# ESP32-S31 register map
Vendor: ESPRESSIF SYSTEMS (SHANGHAI) CO., LTD.; Series: ESP32 S-Series; File version: 1
CPU: RV32IMAFC r0p0, little endian, no MPU, FPU, 0 interrupt priority bits
Address unit: 32 bits
Registers are 32-bit, read-write, reset 0x0 unless marked. A register's access mark holds for its fields unless they carry their own. Offsets are from the block's base; [hi:lo] are bit positions; {n}, {i} and the like mark numbered series.

## KEYMNG — KEYMNG Peripheral
Base 0x20506000
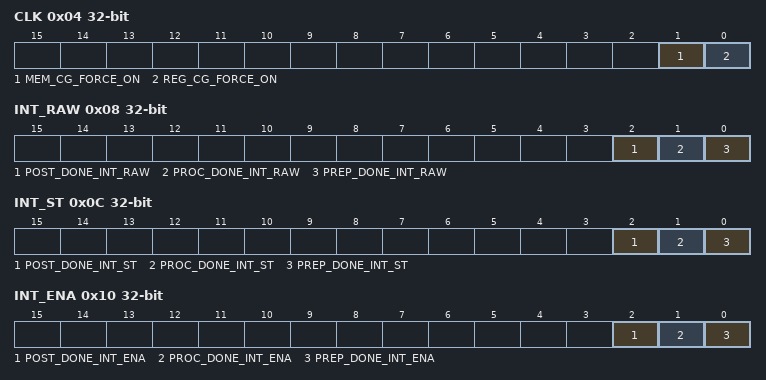
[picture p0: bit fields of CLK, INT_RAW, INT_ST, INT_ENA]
0x04 CLK — Key Manager clock gate control register
  [1] MEM_CG_FORCE_ON — Write 1 to force on memory clock gate.
  [0] REG_CG_FORCE_ON — Write 1 to force on register clock gate.
0x08 INT_RAW ro — Key Manager interrupt raw register, valid in level.
  [2] POST_DONE_INT_RAW — The raw interrupt status bit for the km_post_done_int interrupt
  [1] PROC_DONE_INT_RAW — The raw interrupt status bit for the km_proc_done_int interrupt
  [0] PREP_DONE_INT_RAW — The raw interrupt status bit for the km_prep_done_int interrupt
0x0C INT_ST ro — Key Manager interrupt status register.
  [2] POST_DONE_INT_ST — The masked interrupt status bit for the km_post_done_int interrupt
  [1] PROC_DONE_INT_ST — The masked interrupt status bit for the km_proc_done_int interrupt
  [0] PREP_DONE_INT_ST — The masked interrupt status bit for the km_prep_done_int interrupt
0x10 INT_ENA — Key Manager interrupt enable register.
  [2] POST_DONE_INT_ENA — The interrupt enable bit for the km_post_done_int interrupt
  [1] PROC_DONE_INT_ENA — The interrupt enable bit for the km_proc_done_int interrupt
  [0] PREP_DONE_INT_ENA — The interrupt enable bit for the km_prep_done_int interrupt
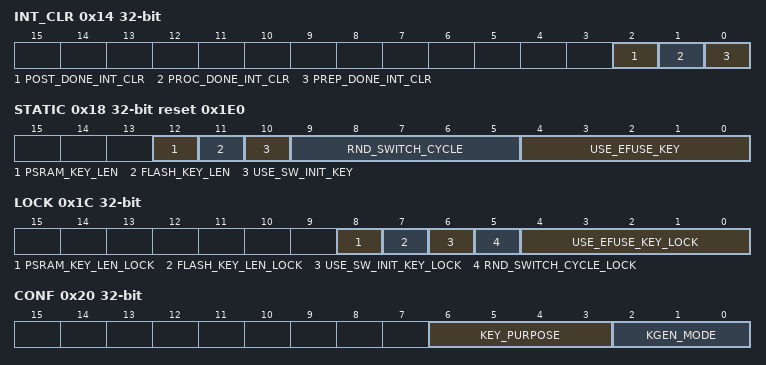
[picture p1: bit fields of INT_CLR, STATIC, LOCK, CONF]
0x14 INT_CLR wo — Key Manager interrupt clear register.
  [2] POST_DONE_INT_CLR — Set this bit to clear the km_post_done_int interrupt
  [1] PROC_DONE_INT_CLR — Set this bit to clear the km_proc_done_int interrupt
  [0] PREP_DONE_INT_CLR — Set this bit to clear the km_prep_done_int interrupt
0x18 STATIC reset 0x1E0 — Key Manager static configuration register
  [12] PSRAM_KEY_LEN — Set this bit to choose psram crypt using xts-aes-256 or xts-aes-128. 1: use xts-aes-256. 0: use xts-aes-128.
  [11] FLASH_KEY_LEN — Set this bit to choose flash crypt using xts-aes-256 or xts-aes-128. 1: use xts-aes-256. 0: use xts-aes-128.
  [10] USE_SW_INIT_KEY — Set this bit to use software written init key instead of efuse_init_key.
  [9:5] RND_SWITCH_CYCLE — The core clock cycle number to sample one rng input data. Please set it bigger than the clock cycle ratio: T_rng/T_km
  [4:0] USE_EFUSE_KEY — Set each bit to choose efuse key instead of key manager deployed key. Each bit stands for a key type:bit 4 for psram_key; bit 3 for ds_key; bit 2 for hmac_key; bit 1 for flash_key; bit 0 for ecdsa_key
0x1C LOCK — Key Manager static configuration locker register
  [8] PSRAM_KEY_LEN_LOCK — Write 1 to lock reg_psram_key_len.
  [7] FLASH_KEY_LEN_LOCK — Write 1 to lock reg_flash_key_len.
  [6] USE_SW_INIT_KEY_LOCK — Write 1 to lock reg_use_sw_init_key.
  [5] RND_SWITCH_CYCLE_LOCK — Write 1 to lock reg_rnd_switch_cycle.
  [4:0] USE_EFUSE_KEY_LOCK — Write 1 to lock reg_use_efuse_key. Each bit locks the corresponding bit of reg_use_efuse_key.
0x20 CONF — Key Manager configuration register
  [6:3] KEY_PURPOSE — Set this field to choose the key purpose. 1: ecdsa_key_192. 2: ecdsa_key_256. 3: flash_256_1_key. 4: flash_256_2_key. 5: flash_128_key. 6: hmac_key. 7: ds_key. 8: psram_256_1_key. 9: psram_256_2_key. 10: psram_128_key. 11: ecdsa_key_384_l. 12: ecdsa_key_384_h. 13: aes 14: mspi_lsfr 15: rma_nonce. Others: reserved.
  [2:0] KGEN_MODE — Set this field to choose the key generator deployment mode. 0: random mode. 1: AES mode. 2: ECDH0 mode. 3: ECDH1 mode. 4: recover mode. 5: export mode. 6-7: reserved.
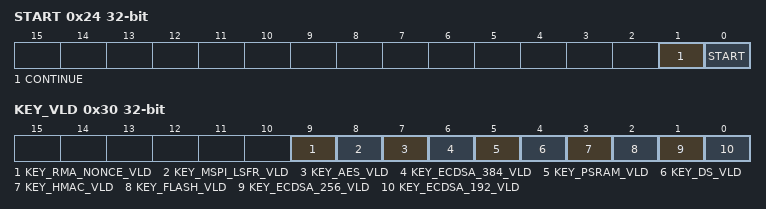
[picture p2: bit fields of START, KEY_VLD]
0x24 START wo — Key Manager control register
  [1] CONTINUE — Write 1 to start Key Manager at IDLE state.
  [0] START — Write 1 to continue Key Manager operation at LOAD/GAIN state.
0x28 STATE ro — Key Manager state register
  [1:0] STATE — The state of Key Manager. 0: IDLE. 1: LOAD. 2: GAIN. 3: BUSY.
0x2C RESULT ro — Key Manager operation result register
  [0] PROC_RESULT — The procedure result bit of Key Manager, only valid when Key Manager procedure is done. 1: Key Manager procedure succeeded. 0: Key Manager procedure failed.
0x30 KEY_VLD ro — Key Manager key status register
  [9] KEY_RMA_NONCE_VLD — The status bit for key_rma_nonce. 1: The key has been deployed correctly. 0: The key has not been deployed yet.
  [8] KEY_MSPI_LSFR_VLD — The status bit for key_mspi_lsfr. 1: The key has been deployed correctly. 0: The key has not been deployed yet.
  [7] KEY_AES_VLD — The status bit for key_aes. 1: The key has been deployed correctly. 0: The key has not been deployed yet.
  [6] KEY_ECDSA_384_VLD — The status bit for key_ecdsa_384. 1: The key has been deployed correctly. 0: The key has not been deployed yet.
  [5] KEY_PSRAM_VLD — The status bit for key_psram. 1: The key has been deployed correctly. 0: The key has not been deployed yet.
  [4] KEY_DS_VLD — The status bit for key_ds. 1: The key has been deployed correctly. 0: The key has not been deployed yet.
  [3] KEY_HMAC_VLD — The status bit for key_hmac. 1: The key has been deployed correctly. 0: The key has not been deployed yet.
  [2] KEY_FLASH_VLD — The status bit for key_flash. 1: The key has been deployed correctly. 0: The key has not been deployed yet.
  [1] KEY_ECDSA_256_VLD — The status bit for key_ecdsa_256. 1: The key has been deployed correctly. 0: The key has not been deployed yet.
  [0] KEY_ECDSA_192_VLD — The status bit for key_ecdsa_192. 1: The key has been deployed correctly. 0: The key has not been deployed yet.
0x34 HUK_VLD ro — Key Manager HUK status register
  [0] HUK_VALID — The HUK status. 0: HUK is not valid. 1: HUK is valid.
0x38 TIMEOUT_LIMIT reset 0xFFFFFFFF — KEYMNG timeout limit configurate register
  [31:0] TIMEOUT_LIMIT — The timeout limitation for waiting sub-IP.
0xFC DATE reset 0x2508190 — Version control register
  [27:0] DATE — Key Manager version control register.
{0x100+i} ASSIST_INFO_MEM[{i}] (i=0..63) 8-bit access not given — The memory that stores assist key info.
{0x140+i} PUBLIC_INFO_MEM[{i}] (i=0..63) 8-bit access not given — The memory that stores public key info.
{0x180+i} SW_INIT_KEY_MEM[{i}] (i=0..31) 8-bit access not given — The memory that stores software written init key.
